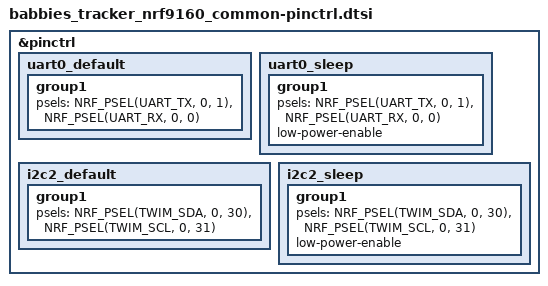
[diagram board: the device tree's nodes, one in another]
&pinctrl {
    /* UART0 configuration */
    uart0_default: uart0_default {
        group1 {
            psels = <NRF_PSEL(UART_TX, 0, 1)>,  /* TX on P0.01 */
                    <NRF_PSEL(UART_RX, 0, 0)>;  /* RX on P0.00 */
        };
    };

    uart0_sleep: uart0_sleep {
        group1 {
            psels = <NRF_PSEL(UART_TX, 0, 1)>,
                    <NRF_PSEL(UART_RX, 0, 0)>;
            low-power-enable; /* Disconnect input buffers to save power */
        };
    };

    /* I2C2 configuration (Example) */
    i2c2_default: i2c2_default {
        group1 {
            psels = <NRF_PSEL(TWIM_SDA, 0, 30)>, /* SDA on P0.30 */
                    <NRF_PSEL(TWIM_SCL, 0, 31)>; /* SCL on P0.31 */
        };
    };

    i2c2_sleep: i2c2_sleep {
        group1 {
            psels = <NRF_PSEL(TWIM_SDA, 0, 30)>,
                    <NRF_PSEL(TWIM_SCL, 0, 31)>;
            low-power-enable;
        };
    };
};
